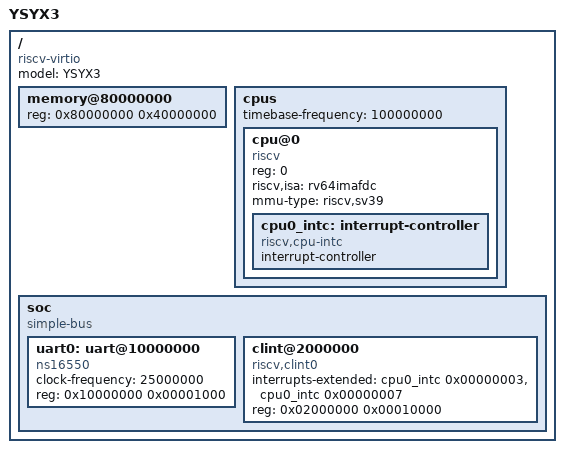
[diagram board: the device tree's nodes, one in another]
// SPDX-License-Identifier: GPL-2.0+

/dts-v1/;

/ {
  #address-cells = <1>;
  #size-cells = <1>;
  compatible = "riscv-virtio";
  model = "YSYX3";
//  chosen {
//    stdout-path = &uart0;
//  };
  memory@80000000 {
    device_type = "memory";
    reg = <0x80000000 0x40000000>;
  };
  cpus {
    #address-cells = <1>;
    #size-cells = <0>;
    timebase-frequency = <100000000>;
    cpu@0 {
      phandle = <0x00000001>;
      device_type = "cpu";
      reg = <0>;
      status = "okay";
      compatible = "riscv";
      riscv,isa = "rv64imafdc";
      mmu-type = "riscv,sv39";
      cpu0_intc: interrupt-controller {
        #address-cells = <1>;
        #interrupt-cells = <1>;
        interrupt-controller;
        compatible = "riscv,cpu-intc";
        phandle = <0x00000002>;
      };
    };
  };
  soc {
    #address-cells = <1>;
    #size-cells = <1>;
    compatible = "simple-bus";
    ranges;
    uart0: uart@10000000 {
      clock-frequency = <25000000>;
      reg = <0x10000000 0x00001000>;
      compatible = "ns16550";
    };
//    spi0: spi@10001000 {
//      #address-cells = <1>;
//      #size-cells = <0>;
//      compatible = "nutshell,spi-1.0";
//      reg = <0x10001000 0x1000>;
//
//      sd@0 {
//        compatible = "mmc-spi-slot";
//        spi-max-frequency = <1000000>;
//        reg = <0>;
//      };
//    };
    clint@2000000 {
      interrupts-extended = <&cpu0_intc 0x00000003 &cpu0_intc 0x00000007>;
      reg = <0x02000000 0x00010000>;
      compatible = "riscv,clint0";
    };
  };
};
